# SF32LB57x register map
File version: 1.0
CPU: CM33 r0p1, little endian, MPU, FPU, 3 interrupt priority bits
Registers are 32-bit, read-write, reset 0x0 unless marked. A register's access mark holds for its fields unless they carry their own. Offsets are from the block's base; [hi:lo] are bit positions; {n}, {i} and the like mark numbered series.

## AUDPRC
Base 0x50087000
0x00 ID reset 0xA0000
  [31:0] REV — revision id
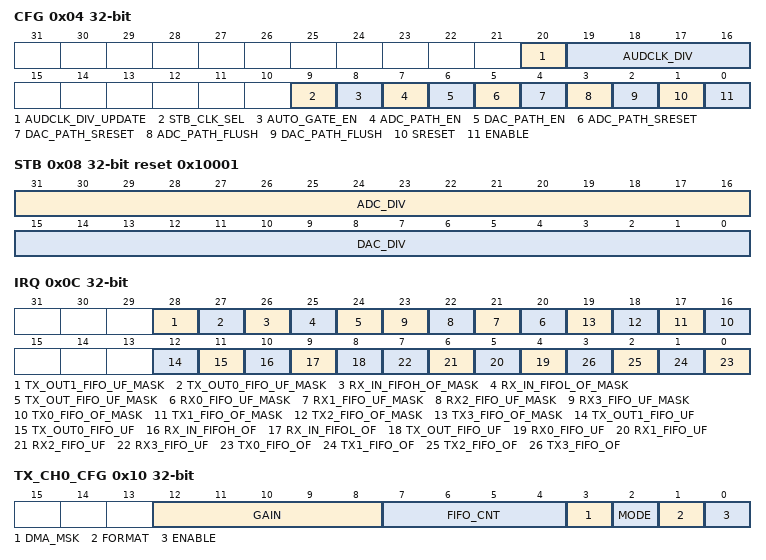
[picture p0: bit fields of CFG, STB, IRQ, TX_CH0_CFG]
0x04 CFG
  [20] AUDCLK_DIV_UPDATE — audprc clock divider update, write 1 to update
  [19:16] AUDCLK_DIV — audprc clock divider, 0 and 1 means divide by 1
  [9] STB_CLK_SEL — audio strobe clock select 0: use xtal clock to generate strobe 1: use pll clock to generate strobe
  [8] AUTO_GATE_EN — auto clock gating enable, high active
  [7] ADC_PATH_EN — adc path enable
  [6] DAC_PATH_EN — dac path enable
  [5] ADC_PATH_SRESET — adc path software reset, high active
  [4] DAC_PATH_SRESET — dac path software reset, high active
  [3] ADC_PATH_FLUSH — adc path fifo flush, high active
  [2] DAC_PATH_FLUSH — dac path fifo flush, high active
  [1] SRESET — audprc software reset, high active
  [0] ENABLE — audprc enable
0x08 STB reset 0x10001
  [31:16] ADC_DIV — adc strobe divider
  [15:0] DAC_DIV — dac strobe divider
0x0C IRQ
  [28] TX_OUT1_FIFO_UF_MASK — tx_out channel 1 fifo underflow mask, 0: mask the interrupt
  [27] TX_OUT0_FIFO_UF_MASK — tx_out channel 0 fifo underflow mask, 0: mask the interrupt
  [26] RX_IN_FIFOH_OF_MASK — rx input fifoh overflow mask, 0: mask the interrupt
  [25] RX_IN_FIFOL_OF_MASK — rx input fifol overflow mask, 0: mask the interrupt
  [24] TX_OUT_FIFO_UF_MASK — tx output fifo underflow mask, 0: mask the interrupt
  [n+20] RX{n}_FIFO_UF_MASK (n=0..3) — rx channel {n} fifo underflow mask, 0: mask the interrupt
  [n+16] TX{n}_FIFO_OF_MASK (n=0..3) — tx channel {n} fifo overflow mask, 0: mask the interrupt
  [12] TX_OUT1_FIFO_UF — tx_out channel 1 fifo underflow, write 1 to clear
  [11] TX_OUT0_FIFO_UF — tx_out channel 0 fifo underflow, write 1 to clear
  [10] RX_IN_FIFOH_OF — rx input fifoh overflow, write 1 to clear
  [9] RX_IN_FIFOL_OF — rx input fifol overflow, write 1 to clear
  [8] TX_OUT_FIFO_UF — tx output fifo underflow, write 1 to clear
  [n+4] RX{n}_FIFO_UF (n=0..3) — rx channel {n} fifo underflow, write 1 to clear
  [n] TX{n}_FIFO_OF (n=0..3) — tx channel {n} fifo overflow, write 1 to clear
0x10 TX_CH0_CFG
  [12:8] GAIN — tx ch0 data gain 5'h0: 0db 5'h1: -1db ...... 5'h1e: -30db 5'h1f: mute
  [7:4] FIFO_CNT — tx fifo counter
  [3] DMA_MSK — 1: mask the dma request for tx ch0
  [2] MODE — tx mode 1'h0: mono mode 1'h1: stereo mode This bit is only used for 16-bit mode, in 24-bit mode, channel can only be set in mono mode. In 16-bit stereo mode, tx channel 1 is not working, both left and right audio data comes from channel 0.
  [1] FORMAT — tx format 0: 16-bit mode 1: 24-bit mode
  [0] ENABLE — tx channel 0 enable
{0x14+8i} TX_CH{i}_ENTRY (i=0..3)
  [31:0] DATA — tx channel {i} data entry
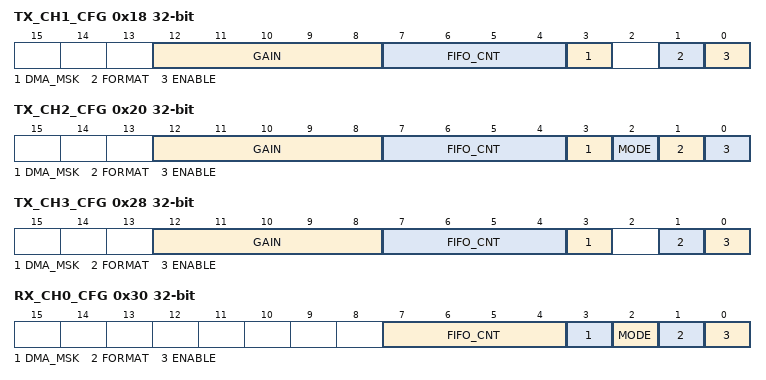
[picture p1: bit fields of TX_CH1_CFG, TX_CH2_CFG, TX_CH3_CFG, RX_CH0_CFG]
0x18 TX_CH1_CFG
  [12:8] GAIN — tx ch1 data gain, this also control the tx ch1 gain when tx ch0 is set as stereo mode 5'h0: 0db 5'h1: -1db ...... 5'h1e: -30db 5'h1f: mute
  [7:4] FIFO_CNT — tx fifo counter
  [3] DMA_MSK — 1: mask the dma request for tx ch1
  [1] FORMAT — tx format 0: 16-bit mode 1: 24-bit mode
  [0] ENABLE — tx channel 0 enable
0x20 TX_CH2_CFG
  [12:8] GAIN — tx ch2 data gain 5'h0: 0db 5'h1: -1db ...... 5'h1e: -6db 5'h1f: mute
  [7:4] FIFO_CNT — tx fifo counter
  [3] DMA_MSK — 1: mask the dma request for tx ch2
  [2] MODE — tx mode 1'h0: mono mode 1'h1: stereo mode This bit is only used for 16-bit mode, in 24-bit mode, channel can only be set in mono mode. In 16-bit stereo mode, tx channel 3 is not working, both left and right audio data comes from channel 2.
  [1] FORMAT — tx format 0: 16-bit mode 1: 24-bit mode
  [0] ENABLE — tx channel 0 enable
0x28 TX_CH3_CFG
  [12:8] GAIN — tx ch3 data gain, this also control the tx ch3 gain when tx ch2 is set as stereo mode 5'h0: 0db 5'h1: -1db ...... 5'h1e: -30db 5'h1f: mute
  [7:4] FIFO_CNT — tx fifo counter
  [3] DMA_MSK — 1: mask the dma request for tx ch3
  [1] FORMAT — tx format 0: 16-bit mode 1: 24-bit mode
  [0] ENABLE — tx channel 0 enable
0x30 RX_CH0_CFG
  [7:4] FIFO_CNT — rx fifo counter
  [3] DMA_MSK — 1: mask the dma request for rx ch0
  [2] MODE — rx mode 1'h0: mono mode 1'h1: stereo mode This bit is only used for 16-bit mode, in 24-bit mode, channel can only be set in mono mode. In 16-bit stereo mode, rx channel 1 is not working, both left and right audio data comes from channel 0.
  [1] FORMAT — rx format 0: 16-bit mode 1: 24-bit mode
  [0] ENABLE — rx channel 0 enable
0x34 RX_CH0_ENTRY
  [31:0] DATA — rx channel 0 data entry
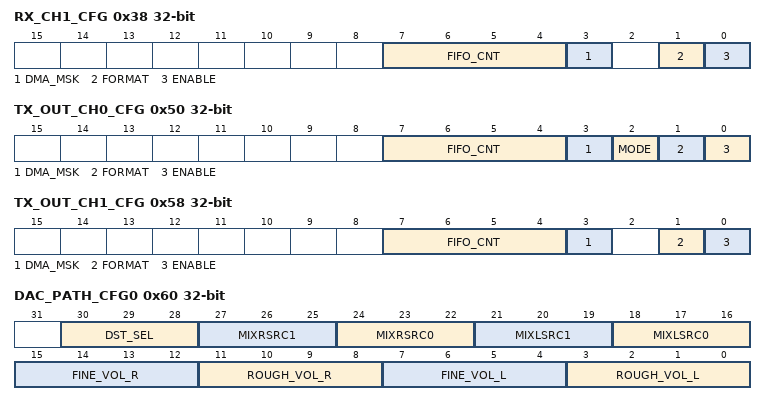
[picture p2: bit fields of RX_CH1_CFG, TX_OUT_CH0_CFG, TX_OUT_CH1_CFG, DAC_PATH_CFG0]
0x38 RX_CH1_CFG
  [7:4] FIFO_CNT — rx fifo counter
  [3] DMA_MSK — 1: mask the dma request for rx ch1
  [1] FORMAT — rx format 0: 16-bit mode 1: 24-bit mode
  [0] ENABLE — rx channel 1 enable
0x3C RX_CH1_ENTRY
  [31:0] DATA — rx channel 1 data entry
0x50 TX_OUT_CH0_CFG
  [7:4] FIFO_CNT — tx out fifo counter
  [3] DMA_MSK — 1: mask the dma request for tx out ch0
  [2] MODE — tx out mode 1'h0: mono mode 1'h1: stereo mode This bit is only used for 16-bit mode, in 24-bit mode, channel can only be set in mono mode. In 16-bit stereo mode, rx channel 1 is not working, both left and right audio data comes from channel 0.
  [1] FORMAT — tx out format 0: 16-bit mode 1: 24-bit mode
  [0] ENABLE — tx out channel 0 enable
0x54 TX_OUT_CH0_ENTRY
  [31:0] DATA — tx out channel 0 data entry
0x58 TX_OUT_CH1_CFG
  [7:4] FIFO_CNT — tx out fifo counter
  [3] DMA_MSK — 1: mask the dma request for tx out ch1
  [1] FORMAT — tx out format 0: 16-bit mode 1: 24-bit mode
  [0] ENABLE — tx out channel 1 enable
0x5C TX_OUT_CH1_ENTRY
  [31:0] DATA — tx out channel 1 data entry
0x60 DAC_PATH_CFG0
  [30:28] DST_SEL — dac path destination select 3'h0: select audio codec only 3'h1: select external interface only 3'h2: select apb interface only 3'h3: reserved 3'h4: selece audio codec and apb interface simultaneously 3'h5: select external interface and apb interface simultaneously 3'h6, 3'h7: reserved
  [27:25] MIXRSRC1 — dac mixer right channel input source0 select 3'h0:tx ch0 3'h1:tx ch1 3'h2:tx ch2 3'h3:tx ch3 3'h4:mute other: mute
  [24:22] MIXRSRC0 — dac mixer right channel input source0 select 3'h0:tx ch0 3'h1:tx ch1 3'h2:tx ch2 3'h3:tx ch3 3'h4:mute other: mute
  [21:19] MIXLSRC1 — dac mixer left channel input source1 select 3'h0:tx ch0 3'h1:tx ch1 3'h2:tx ch2 3'h3:tx ch3 3'h4:mute other: mute
  [18:16] MIXLSRC0 — dac mixer left channel input source0 select 3'h0:tx ch0 3'h1:tx ch1 3'h2:tx ch2 3'h3:tx ch3 3'h4:mute other: mute
  [15:12] FINE_VOL_R — dac mixer right channel fine volume control range from 0dB to 6dB step is 0.5dB 4'h0: 0dB 4'h1: 0.5dB ...... 4'hb: 5.5dB 4'hc, 4'hd, 4'he, 4'hf: mute
  [11:8] ROUGH_VOL_R — dac mixer right channel rough volume control range from -36dB to 54dB step is 6dB 4'h0: -36dB 4'h1: -30dB ...... 4'h6: 0dB ...... 4'he: 48dB 4'hf: 54dB
  [7:4] FINE_VOL_L — dac mixer left channel fine volume control range from 0dB to 6dB step is 0.5dB 4'h0: 0dB 4'h1: 0.5dB ...... 4'hb: 5.5dB 4'hc, 4'hd, 4'he, 4'hf: mute
  [3:0] ROUGH_VOL_L — dac mixer left channel rough volume control range from -36dB to 54dB step is 6dB 4'h0: -36dB 4'h1: -30dB ...... 4'h6: 0dB ...... 4'he: 48dB 4'hf: 54dB
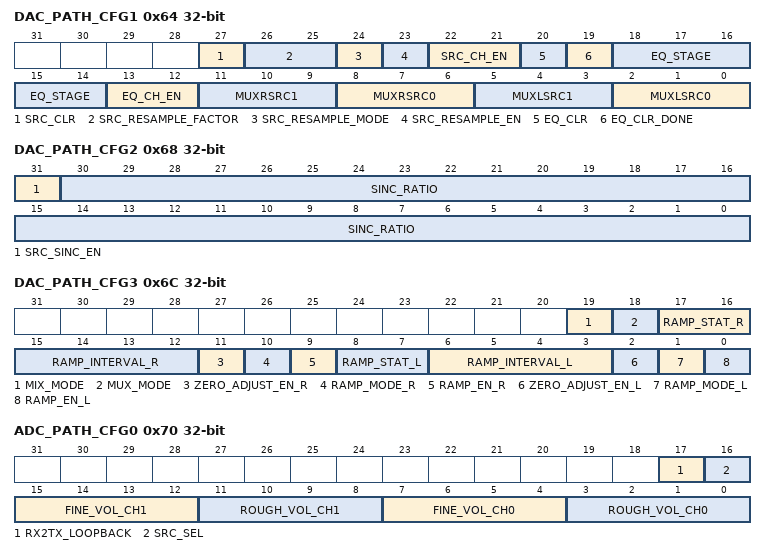
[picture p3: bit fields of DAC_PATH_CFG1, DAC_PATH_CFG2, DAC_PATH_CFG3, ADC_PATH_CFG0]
0x64 DAC_PATH_CFG1
  [27] SRC_CLR — 1: clear src logic 0: normal operation
  [26:25] SRC_RESAMPLE_FACTOR — resample factor 0: factor = 2 1: factor = 4 2: factor = 8 3: reserved
  [24] SRC_RESAMPLE_MODE — 1: downsample mode 0: upsample mode
  [23] SRC_RESAMPLE_EN — 1: enable resample module
  [22:21] SRC_CH_EN — source rate converter channel enable
  [20] EQ_CLR — equalizer clear request
  [19] EQ_CLR_DONE — equalizer clear done flag
  [18:14] EQ_STAGE — set equalizer stage, max is 16.
  [13:12] EQ_CH_EN — equalizer channel enable 2'b11: enable both channel 2'b10: enable right chanel only 2'b01: enable left channel only 2'b00: bypass equalizer
  [11:9] MUXRSRC1 — dac mux right channel input source0 select 3'h0:tx ch0 3'h1:tx ch1 3'h2:rx ch0 3'h3:rx ch1 3'h4:mute other: mute
  [8:6] MUXRSRC0 — dac mux right channel input source0 select 3'h0:tx ch0 3'h1:tx ch1 3'h2:rx ch0 3'h3:rx ch1 3'h4:mute other: mute
  [5:3] MUXLSRC1 — dac mux left channel input source1 select 3'h0:tx ch0 3'h1:tx ch1 3'h2:rx ch0 3'h3:rx ch1 3'h4:mute other: mute
  [2:0] MUXLSRC0 — dac mux left channel input source0 select 3'h0:tx ch0 3'h1:tx ch1 3'h2:rx ch0 3'h3:rx ch1 3'h4:mute other: mute
0x68 DAC_PATH_CFG2
  [31] SRC_SINC_EN — sinc filter enable
  [30:0] SINC_RATIO — sinc filter ratio, s31.30 format. Range from 0~2 ratio = SincFreqin/SincFreqout
0x6C DAC_PATH_CFG3
  [19] MIX_MODE — dac mixer mode. 1'h0: c = a + b 1'h1: if a,b are negative c = a + b + (a*b/2^24) else c = a + b - (a*b/2^24)
  [18] MUX_MODE — dac mux mode. 1'h0: c = a + b 1'h1: if a,b are negative c = a + b + (a*b/2^24) else c = a + b - (a*b/2^24)
  [17:16] RAMP_STAT_R — dac mixer right channel ramp module status
  [15:12] RAMP_INTERVAL_R — dac mixer right channel volume ramp interval.
  [11] ZERO_ADJUST_EN_R — dac mixer right channel volume adjustment during 0 volume cross enable
  [10] RAMP_MODE_R — dac mixer right channel volume ramp mode: 1: slowly ramp to target volume. Step is 0.5db 0: directly ramp to target volume.
  [9] RAMP_EN_R — dac mixer right channel volume ramp enable
  [8:7] RAMP_STAT_L — dac mixer left channel ramp module status
  [6:3] RAMP_INTERVAL_L — dac mixer left channel volume ramp interval.
  [2] ZERO_ADJUST_EN_L — dac mixer left channel volume adjustment during 0 volume cross enable
  [1] RAMP_MODE_L — dac mixer left channel volume ramp mode: 1: slowly ramp to target volume. Step is 0.5db 0: directly ramp to target volume.
  [0] RAMP_EN_L — dac mixer left channel volume ramp enable
0x70 ADC_PATH_CFG0
  [17] RX2TX_LOOPBACK — rx to tx loopback enable
  [16] SRC_SEL — adc path source select 1'h0: select audio codec 1'h1: select external interface
  [15:12] FINE_VOL_CH1 — adc ch1 channel fine volume control range from 0dB to 6dB step is 0.5dB 4'h0: 0dB 4'h1: 0.5dB ...... 4'hb: 5.5dB 4'hc, 4'hd, 4'he, 4'hf: mute
  [11:8] ROUGH_VOL_CH1 — adc ch1 channel rough volume control range from -36dB to 54dB step is 6dB 4'h0: -36dB 4'h1: -30dB ...... 4'h6: 0dB ...... 4'he: 48dB 4'hf: 54dB
  [7:4] FINE_VOL_CH0 — adc ch0 channel fine volume control range from 0dB to 6dB step is 0.5dB 4'h0: 0dB 4'h1: 0.5dB ...... 4'hb: 5.5dB 4'hc, 4'hd, 4'he, 4'hf: mute
  [3:0] ROUGH_VOL_CH0 — adc ch0 channel rough volume control range from -36dB to 54dB step is 6dB 4'h0: -36dB 4'h1: -30dB ...... 4'h6: 0dB ...... 4'he: 48dB 4'hf: 54dB
0x80 DAC_EQ_CFG0
  [23:0] COEF — s1 b0 coef
0x84 DAC_EQ_CFG1
  [23:0] COEF — s1 b1 coef
0x88 DAC_EQ_CFG2
  [23:0] COEF — s1 a1 coef
0x8C DAC_EQ_CFG3
  [23:0] COEF — s1 b2 coef
0x90 DAC_EQ_CFG4
  [23:0] COEF — s1 a2 coef
0x94 DAC_EQ_CFG5
  [23:0] COEF — s2 b0 coef
0x98 DAC_EQ_CFG6
  [23:0] COEF — s2 b1 coef
0x9C DAC_EQ_CFG7
  [23:0] COEF — s2 a1 coef
0xA0 DAC_EQ_CFG8
  [23:0] COEF — s2 b2 coef
0xA4 DAC_EQ_CFG9
  [23:0] COEF — s2 a2 coef
0xA8 DAC_EQ_CFG10
  [23:0] COEF — s3 b0 coef
0xAC DAC_EQ_CFG11
  [23:0] COEF — s3 b1 coef
0xB0 DAC_EQ_CFG12
  [23:0] COEF — s3 a1 coef
0xB4 DAC_EQ_CFG13
  [23:0] COEF — s3 b2 coef
0xB8 DAC_EQ_CFG14
  [23:0] COEF — s3 a2 coef
0xBC DAC_EQ_CFG15
  [23:0] COEF — s4 b0 coef
0xC0 DAC_EQ_CFG16
  [23:0] COEF — s4 b1 coef
0xC4 DAC_EQ_CFG17
  [23:0] COEF — s4 a1 coef
0xC8 DAC_EQ_CFG18
  [23:0] COEF — s4 b2 coef
0xCC DAC_EQ_CFG19
  [23:0] COEF — s4 a2 coef
0xD0 DAC_EQ_CFG20
  [23:0] COEF — s5 b0 coef
0xD4 DAC_EQ_CFG21
  [23:0] COEF — s5 b1 coef
0xD8 DAC_EQ_CFG22
  [23:0] COEF — s5 a1 coef
0xDC DAC_EQ_CFG23
  [23:0] COEF — s5 b2 coef
0xE0 DAC_EQ_CFG24
  [23:0] COEF — s5 a2 coef
0xE4 DAC_EQ_CFG25
  [23:0] COEF — s6 b0 coef
0xE8 DAC_EQ_CFG26
  [23:0] COEF — s6 b1 coef
0xEC DAC_EQ_CFG27
  [23:0] COEF — s6 a1 coef
0xF0 DAC_EQ_CFG28
  [23:0] COEF — s6 b2 coef
0xF4 DAC_EQ_CFG29
  [23:0] COEF — s6 a2 coef
0xF8 DAC_EQ_CFG30
  [23:0] COEF — s7 b0 coef
0xFC DAC_EQ_CFG31
  [23:0] COEF — s7 b1 coef
0x100 DAC_EQ_CFG32
  [23:0] COEF — s7 a1 coef
0x104 DAC_EQ_CFG33
  [23:0] COEF — s7 b2 coef
0x108 DAC_EQ_CFG34
  [23:0] COEF — s7 a2 coef
0x10C DAC_EQ_CFG35
  [23:0] COEF — s8 b0 coef
0x110 DAC_EQ_CFG36
  [23:0] COEF — s8 b1 coef
0x114 DAC_EQ_CFG37
  [23:0] COEF — s8 a1 coef
0x118 DAC_EQ_CFG38
  [23:0] COEF — s8 b2 coef
0x11C DAC_EQ_CFG39
  [23:0] COEF — s8 a2 coef
0x120 DAC_EQ_CFG40
  [23:0] COEF — s9 b0 coef
0x124 DAC_EQ_CFG41
  [23:0] COEF — s9 b1 coef
0x128 DAC_EQ_CFG42
  [23:0] COEF — s9 a1 coef
0x12C DAC_EQ_CFG43
  [23:0] COEF — s9 b2 coef
0x130 DAC_EQ_CFG44
  [23:0] COEF — s9 a2 coef
0x134 DAC_EQ_CFG45
  [23:0] COEF — s10 b0 coef
0x138 DAC_EQ_CFG46
  [23:0] COEF — s10 b1 coef
0x13C DAC_EQ_CFG47
  [23:0] COEF — s10 a1 coef
0x140 DAC_EQ_CFG48
  [23:0] COEF — s10 b2 coef
0x144 DAC_EQ_CFG49
  [23:0] COEF — s10 a2 coef
0x148 DAC_EQ_CFG50
  [23:0] COEF — s11 b0 coef
0x14C DAC_EQ_CFG51
  [23:0] COEF — s11 b1 coef
0x150 DAC_EQ_CFG52
  [23:0] COEF — s11 a1 coef
0x154 DAC_EQ_CFG53
  [23:0] COEF — s11 b2 coef
0x158 DAC_EQ_CFG54
  [23:0] COEF — s11 a2 coef
0x15C DAC_EQ_CFG55
  [23:0] COEF — s12 b0 coef
0x160 DAC_EQ_CFG56
  [23:0] COEF — s12 b1 coef
0x164 DAC_EQ_CFG57
  [23:0] COEF — s12 a1 coef
0x168 DAC_EQ_CFG58
  [23:0] COEF — s12 b2 coef
0x16C DAC_EQ_CFG59
  [23:0] COEF — s12 a2 coef
0x170 DAC_EQ_CFG60
  [23:0] COEF — s13 b0 coef
0x174 DAC_EQ_CFG61
  [23:0] COEF — s13 b1 coef
0x178 DAC_EQ_CFG62
  [23:0] COEF — s13 a1 coef
0x17C DAC_EQ_CFG63
  [23:0] COEF — s13 b2 coef
0x180 DAC_EQ_CFG64
  [23:0] COEF — s13 a2 coef
0x184 DAC_EQ_CFG65
  [23:0] COEF — s14 b0 coef
0x188 DAC_EQ_CFG66
  [23:0] COEF — s14 b1 coef
0x18C DAC_EQ_CFG67
  [23:0] COEF — s14 a1 coef
0x190 DAC_EQ_CFG68
  [23:0] COEF — s14 b2 coef
0x194 DAC_EQ_CFG69
  [23:0] COEF — s14 a2 coef
0x198 DAC_EQ_CFG70
  [23:0] COEF — s15 b0 coef
0x19C DAC_EQ_CFG71
  [23:0] COEF — s15 b1 coef
0x1A0 DAC_EQ_CFG72
  [23:0] COEF — s15 a1 coef
0x1A4 DAC_EQ_CFG73
  [23:0] COEF — s15 b2 coef
0x1A8 DAC_EQ_CFG74
  [23:0] COEF — s15 a2 coef
0x1AC DAC_EQ_CFG75
  [23:0] COEF — s16 b0 coef
0x1B0 DAC_EQ_CFG76
  [23:0] COEF — s16 b1 coef
0x1B4 DAC_EQ_CFG77
  [23:0] COEF — s16 a1 coef
0x1B8 DAC_EQ_CFG78
  [23:0] COEF — s16 b2 coef
0x1BC DAC_EQ_CFG79
  [23:0] COEF — s16 a2 coef
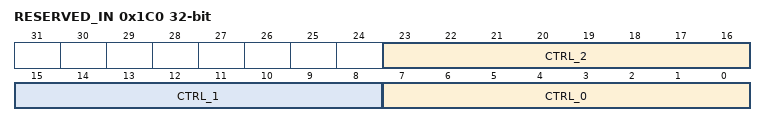
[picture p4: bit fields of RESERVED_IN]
0x1C0 RESERVED_IN
  [23:16] CTRL_2 — reserved control 2
  [15:8] CTRL_1 — reserved control 1
  [7:0] CTRL_0 — reserved control 0
0x1C4 RESERVED_OUT
  [7:0] STAT — reserved status
